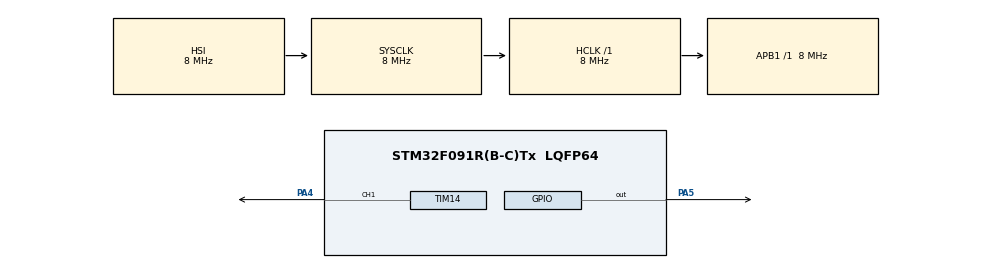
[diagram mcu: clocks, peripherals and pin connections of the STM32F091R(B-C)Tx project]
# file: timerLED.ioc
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Mcu.Family=STM32F0
Mcu.Name=STM32F091R(B-C)Tx
Mcu.Package=LQFP64
NVIC.TIM14_IRQn=true\:0\:0\:false\:false\:true\:true\:true
PA4.Signal=S_TIM14_CH1
PA5.Signal=GPIO_Output
ProjectManager.HeapSize=0x200
ProjectManager.StackSize=0x400
ProjectManager.TargetToolchain=SW4STM32
RCC.AHBFreq_Value=8000000
RCC.APB1Freq_Value=8000000
RCC.APB1TimFreq_Value=8000000
RCC.FLatency-AdvancedSettings=FLASH_LATENCY_0
RCC.HCLKFreq_Value=8000000
RCC.PLLDivider=RCC_PREDIV_DIV2
RCC.PLLMUL=RCC_PLL_MUL12
RCC.PREFETCH_ENABLE-AdvancedSettings=1
RCC.SYSCLKFreq_VALUE=8000000
SH.S_TIM14_CH1.0=TIM14_CH1,Output Compare1 CH1
TIM14.Channel=TIM_CHANNEL_1
TIM14.Period=1000
TIM14.Prescaler=8000
VP_TIM14_VS_ClockSourceINT.Mode=Enable_Timer
board=NUCLEO-F091RC

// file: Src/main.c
/* USER CODE BEGIN Header */
/**
  ******************************************************************************
  * @file           : main.c
  * @brief          : Main program body
  ******************************************************************************
  * @attention
  *
  * <h2><center>&copy; Copyright (c) 2020 STMicroelectronics.
  * All rights reserved.</center></h2>
  *
  * This software component is licensed by ST under BSD 3-Clause license,
  * the "License"; You may not use this file except in compliance with the
  * License. You may obtain a copy of the License at:
  *                        opensource.org/licenses/BSD-3-Clause
  *
  ******************************************************************************
  */
/* USER CODE END Header */

#include "main.h"

TIM_HandleTypeDef htim14;

/* USER CODE BEGIN PV */
uint8_t flag;
/* USER CODE END PV */

void SystemClock_Config(void);
static void MX_GPIO_Init(void);
static void MX_TIM14_Init(void);

int main(void)
{

  /* MCU Configuration--------------------------------------------------------*/

  /* Reset of all peripherals, Initializes the Flash interface and the Systick. */
  HAL_Init();

  /* Configure the system clock */
  SystemClock_Config();

  /* Initialize all configured peripherals */
  MX_GPIO_Init();
  MX_TIM14_Init();
  /* USER CODE BEGIN 2 */
  HAL_TIM_Base_Start_IT(&htim14);
  /* USER CODE END 2 */

  /* Infinite loop */
  while (1)
  {

    /* USER CODE BEGIN 3 */
	  if (flag == 1)  //se tiver passado 1 segundo
	  {
		  HAL_GPIO_TogglePin(GPIOA, GPIO_PIN_5); //toggle LED
		  flag = 0;
	  }
  }
  /* USER CODE END 3 */
}

void SystemClock_Config(void)
{
  RCC_OscInitTypeDef RCC_OscInitStruct = {0};
  RCC_ClkInitTypeDef RCC_ClkInitStruct = {0};

  /** Initializes the CPU, AHB and APB busses clocks
  */
  RCC_OscInitStruct.OscillatorType = RCC_OSCILLATORTYPE_HSI;
  RCC_OscInitStruct.HSIState = RCC_HSI_ON;
  RCC_OscInitStruct.HSICalibrationValue = RCC_HSICALIBRATION_DEFAULT;
  RCC_OscInitStruct.PLL.PLLState = RCC_PLL_NONE;
  if (HAL_RCC_OscConfig(&RCC_OscInitStruct) != HAL_OK)
  {
    Error_Handler();
  }
  /** Initializes the CPU, AHB and APB busses clocks
  */
  RCC_ClkInitStruct.ClockType = RCC_CLOCKTYPE_HCLK|RCC_CLOCKTYPE_SYSCLK
                              |RCC_CLOCKTYPE_PCLK1;
  RCC_ClkInitStruct.SYSCLKSource = RCC_SYSCLKSOURCE_HSI;
  RCC_ClkInitStruct.AHBCLKDivider = RCC_SYSCLK_DIV1;
  RCC_ClkInitStruct.APB1CLKDivider = RCC_HCLK_DIV1;

  if (HAL_RCC_ClockConfig(&RCC_ClkInitStruct, FLASH_LATENCY_0) != HAL_OK)
  {
    Error_Handler();
  }
}

static void MX_TIM14_Init(void)
{

  TIM_OC_InitTypeDef sConfigOC = {0};

  htim14.Instance = TIM14;
  htim14.Init.Prescaler = 8000;
  htim14.Init.CounterMode = TIM_COUNTERMODE_UP;
  htim14.Init.Period = 1000;
  htim14.Init.ClockDivision = TIM_CLOCKDIVISION_DIV1;
  htim14.Init.AutoReloadPreload = TIM_AUTORELOAD_PRELOAD_DISABLE;
  if (HAL_TIM_Base_Init(&htim14) != HAL_OK)
  {
    Error_Handler();
  }
  if (HAL_TIM_OC_Init(&htim14) != HAL_OK)
  {
    Error_Handler();
  }
  sConfigOC.OCMode = TIM_OCMODE_TIMING;
  sConfigOC.Pulse = 0;
  sConfigOC.OCPolarity = TIM_OCPOLARITY_HIGH;
  sConfigOC.OCFastMode = TIM_OCFAST_DISABLE;
  if (HAL_TIM_OC_ConfigChannel(&htim14, &sConfigOC, TIM_CHANNEL_1) != HAL_OK)
  {
    Error_Handler();
  }
  HAL_TIM_MspPostInit(&htim14);

}

static void MX_GPIO_Init(void)
{
  GPIO_InitTypeDef GPIO_InitStruct = {0};

  /* GPIO Ports Clock Enable */
  __HAL_RCC_GPIOA_CLK_ENABLE();

  /*Configure GPIO pin Output Level */
  HAL_GPIO_WritePin(GPIOA, GPIO_PIN_5, GPIO_PIN_RESET);

  /*Configure GPIO pin : PA5 */
  GPIO_InitStruct.Pin = GPIO_PIN_5;
  GPIO_InitStruct.Mode = GPIO_MODE_OUTPUT_PP;
  GPIO_InitStruct.Pull = GPIO_NOPULL;
  GPIO_InitStruct.Speed = GPIO_SPEED_FREQ_LOW;
  HAL_GPIO_Init(GPIOA, &GPIO_InitStruct);

}

/* USER CODE BEGIN 4 */
void HAL_TIM_PeriodElapsedCallback(TIM_HandleTypeDef *htim14) //quando passar 1 perнodo (1 seg neste caso)
{
	flag = 1;
}

/* USER CODE END 4 */

void Error_Handler(void)
{
}

/************************ (C) COPYRIGHT STMicroelectronics *****END OF FILE****/
